# STM32G484xx register map
File version: 1.0
Registers are 32-bit, access not given, reset 0x0 unless marked. A register's access mark holds for its fields unless they carry their own. Offsets are from the block's base; [hi:lo] are bit positions; {n}, {i} and the like mark numbered series.

## DAC3
Base 0x50001000
Same registers: DAC4 0x50001400
0x00 CR
  [31] BWST2, [30] CEN2, [30] CAL_FLAG2, [29] DMAUDRIE2, [29] DMAUDR2, [28] DMAEN2, [28] DORSTAT2, [27] DAC2RDY, [25] SINFORMAT2, [27:24] MAMP2, [24] DMADOUBLE2, [27:24] STINCTRIGSEL2, [23:22] WAVE2, [31:20] DACC1DHRB, [31:20] DACC2DHRB, [31:20] DACC2DHR, [21:18] TSEL2, [17] TEN2, [17] SWTRIGB2, [16] EN2, [16] SWTRIGB1, [27:16] DACC1DHRB, [27:16] DACC2DHRB, [27:16] DACC2DHR, [27:16] DACC1DORB, [27:16] DACC2DORB, [20:16] OTRIM2, [18:16] MODE2, [25:16] THOLD2, [23:16] TREFRESH2, [31:16] STINCDATA1, [31:16] STINCDATA2, [19:16] STRSTTRIGSEL2, [15] HFSEL, [15] BWST1, [14] CEN1, [14] CAL_FLAG1, [15:14] HFSEL, [13] DMAUDRIE1, [13] DMAUDR1, [12] DMAEN1, [12] DORSTAT1, [12] STDIR1, [12] STDIR2, [11] DAC1RDY, [9] SINFORMAT1, [11:8] MAMP1, [15:8] DACC1DHRB, [15:8] DACC2DHRB, [15:8] DACC2DHR, [8] DMADOUBLE1, [11:8] STINCTRIGSEL1, [7:6] WAVE1, [15:4] DACC1DHR, [15:4] DACC2DHR, [15:4] DACC1DHR, [5:2] TSEL1, [1] TEN1, [1] SWTRIG2, [0] EN1, [0] SWTRIG1, [11:0] DACC1DHR, [7:0] DACC1DHR, [11:0] DACC2DHR, [7:0] DACC2DHR, [11:0] DACC1DHR, [7:0] DACC1DHR, [11:0] DACC1DOR, [11:0] DACC2DOR, [4:0] OTRIM1, [2:0] MODE1, [9:0] TSAMPLE1, [9:0] TSAMPLE2, [9:0] THOLD1, [7:0] TREFRESH1, [11:0] STRSTDATA1, [11:0] STRSTDATA2, [3:0] STRSTTRIGSEL1
0x04 SWTRIGR
0x08 DHR12R1
0x0C DHR12L1
0x10 DHR8R1
0x14 DHR12R2
0x18 DHR12L2
0x1C DHR8R2
0x20 DHR12RD
0x24 DHR12LD
0x28 DHR8RD
0x2C DOR1
0x30 DOR2
0x34 SR
0x38 CCR
0x3C MCR
0x40 SHSR1
0x44 SHSR2
0x48 SHHR
0x4C SHRR
0x58 STR1
0x5C STR2
0x60 STMODR

## AES
Base 0x50060000
0x00 CR
  [23:20] NPBLB, [18] KEYSIZE, [14:13] GCMPH, [12] DMAOUTEN, [11] DMAINEN, [10] ERRIE, [9] CCFIE, [8] ERRC, [7] CCFC, [16:5] CHMOD, [4:3] MODE, [3] BUSY, [2] WRERR, [2:1] DATATYPE, [1] RDERR, [0] EN, [0] CCF
0x04 SR
0x08 DINR
0x0C DOUTR
{0x10+4i} KEYR{i} (i=0..3)
{0x20+4i} IVR{i} (i=0..3)
{0x20+4i} KEYR{i} (i=4..7)
{0x40+4i} SUSP{i}R (i=0..7)

## RNG
Base 0x50060800
0x00 CR
  [6] SEIS, [5] CED, [5] CEIS, [3] IE, [2] RNGEN, [2] SECS, [1] CECS, [0] DRDY
0x04 SR
0x08 DR

## FMC_Bank1_R
Base 0xA0000000
0x00 BTCR.0
0x04 BTCR.1
0x08 BTCR.2
0x0C BTCR.3
0x10 BTCR.4
0x14 BTCR.5
0x18 BTCR.6
0x1C BTCR.7
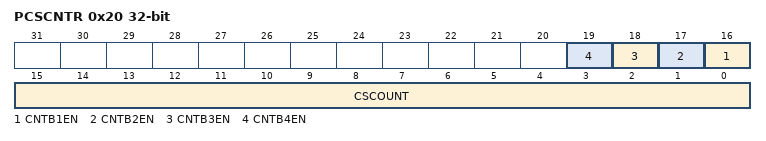
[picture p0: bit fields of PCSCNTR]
0x20 PCSCNTR
  [n+15] CNTB{n}EN (n=1..4), [15:0] CSCOUNT

## FMC_Bank3_R
Base 0xA0000080
0x00 PCR
  [31:24] MEMHIZ, [31:24] ATTHIZ, [19:17] ECCPS, [23:16] MEMHOLD, [23:16] ATTHOLD, [16:13] TAR, [12:9] TCLR, [15:8] MEMWAIT, [15:8] ATTWAIT, [6] ECCEN, [6] FEMPT, [5] IFEN, [5:4] PWID, [4] ILEN, [3] PTYP, [3] IREN, [2] PBKEN, [2] IFS, [1] PWAITEN, [1] ILS, [0] IRS, [7:0] MEMSET, [7:0] ATTSET, [31:0] ECC
0x04 SR
0x08 PMEM
0x0C PATT
0x14 ECCR

## FMC_Bank1E_R
Base 0xA0000104
0x00 BWTR.0
  [31:30] DATAHLD, [31:30] DATAHLD, [31:30] DATAHLD, [31:30] DATAHLD, [31:30] DATAHLD, [31:30] DATAHLD, [31:30] DATAHLD, [29:28] ACCMOD, [29:28] ACCMOD, [29:28] ACCMOD, [29:28] ACCMOD, [29:28] ACCMOD, [29:28] ACCMOD, [29:28] ACCMOD, [19:16] BUSTURN, [19:16] BUSTURN, [19:16] BUSTURN, [19:16] BUSTURN, [19:16] BUSTURN, [19:16] BUSTURN, [19:16] BUSTURN, [15:8] DATAST, [15:8] DATAST, [15:8] DATAST, [15:8] DATAST, [15:8] DATAST, [15:8] DATAST, [15:8] DATAST, [7:4] ADDHLD, [7:4] ADDHLD, [7:4] ADDHLD, [7:4] ADDHLD, [7:4] ADDHLD, [7:4] ADDHLD, [7:4] ADDHLD, [3:0] ADDSET, [3:0] ADDSET, [3:0] ADDSET, [3:0] ADDSET, [3:0] ADDSET, [3:0] ADDSET, [3:0] ADDSET
0x04 BWTR.1
0x08 BWTR.2
0x0C BWTR.3
0x10 BWTR.4
0x14 BWTR.5
0x18 BWTR.6

## QUADSPI
Base 0xA0001000
0x00 CR
  [31] DDRM, [30] DHHC, [28] SIOO, [27:26] FMODE, [31:24] PRESCALER, [25:24] DMODE, [23] PMM, [22] APMS, [20] TOIE, [19] SMIE, [18] FTIE, [22:18] DCYC, [17] TCIE, [16] TEIE, [20:16] FSIZE, [17:16] ABSIZE, [15:14] ABMODE, [13:12] ADSIZE, [11:10] ADMODE, [11:8] FTHRES, [10:8] CSHT, [12:8] FLEVEL, [9:8] IMODE, [7] FSEL, [6] DFM, [5] BUSY, [4] SSHIFT, [4] TOF, [4] CTOF, [3] TCEN, [3] SMF, [3] CSMF, [2] DMAEN, [2] FTF, [1] ABORT, [1] TCF, [1] CTCF, [0] EN, [0] CKMODE, [0] TEF, [0] CTEF, [31:0] DL, [7:0] INSTRUCTION, [31:0] ADDRESS, [31:0] ALTERNATE, [31:0] DATA, [31:0] MASK, [31:0] MATCH, [15:0] INTERVAL, [15:0] TIMEOUT
0x04 DCR
0x08 SR
0x0C FCR
0x10 DLR
0x14 CCR
0x18 AR
0x1C ABR
0x20 DR
0x24 PSMKR
0x28 PSMAR
0x2C PIR
0x30 LPTR

## DBGMCU
Base 0xE0042000
0x00 IDCODE
  [31] DBG_LPTIM1_STOP, [30] DBG_I2C3_STOP, [26] DBG_HRTIM1_STOP, [22] DBG_I2C2_STOP, [21] DBG_I2C1_STOP, [20] DBG_TIM20_STOP, [18] DBG_TIM17_STOP, [17] DBG_TIM16_STOP, [31:16] REV_ID, [16] DBG_TIM15_STOP, [13] DBG_TIM8_STOP, [12] DBG_IWDG_STOP, [11] DBG_WWDG_STOP, [11] DBG_TIM1_STOP, [10] DBG_RTC_STOP, [7:6] TRACE_MODE, [5] TRACE_IOEN, [n-2] DBG_TIM{n}_STOP (n=2..7), [2] DBG_STANDBY, [1] DBG_STOP, [1] DBG_I2C4_STOP, [11:0] DEV_ID, [0] DBG_SLEEP
0x04 CR
0x08 APB1FZR1
0x0C APB1FZR2
0x10 APB2FZ
